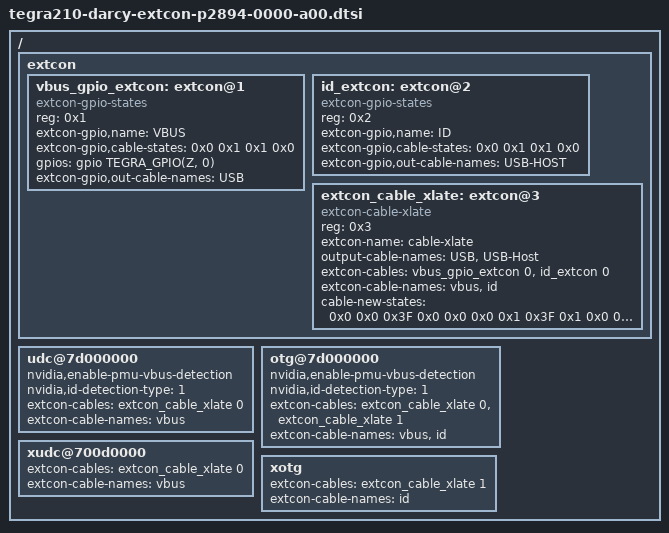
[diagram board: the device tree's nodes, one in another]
/*
 * Copyright (c) 2015-2016, NVIDIA CORPORATION.  All rights reserved.
 *
 * This program is free software; you can redistribute it and/or modify it
 * under the terms and conditions of the GNU General Public License,
 * version 2, as published by the Free Software Foundation.
 *
 * This program is distributed in the hope it will be useful, but WITHOUT
 * ANY WARRANTY; without even the implied warranty of MERCHANTABILITY or
 * FITNESS FOR A PARTICULAR PURPOSE.  See the GNU General Public License for
 * more details.
 */

/ {
	extcon {
		vbus_gpio_extcon: extcon@1 {
			compatible = "extcon-gpio-states";
			reg = <0x1>;
			extcon-gpio,name = "VBUS";
			extcon-gpio,cable-states = <0x0 0x1
						    0x1 0x0>;
			gpios = <&gpio TEGRA_GPIO(Z, 0) 0>;
			extcon-gpio,out-cable-names = "USB";
			#extcon-cells = <1>;
		};

		id_extcon: extcon@2 {
			compatible = "extcon-gpio-states";
			reg = <0x2>;
			extcon-gpio,name = "ID";
			extcon-gpio,cable-states = <0x0 0x1
						0x1 0x0>;
			extcon-gpio,out-cable-names = "USB-HOST";
			#extcon-cells = <1>;
		};

		extcon_cable_xlate: extcon@3 {
			compatible = "extcon-cable-xlate";
			reg = <0x3>;
			extcon-name = "cable-xlate";
			output-cable-names = "USB", "USB-Host";
			extcon-cables = <&vbus_gpio_extcon 0 &id_extcon 0>;
			extcon-cable-names = "vbus", "id";
			cable-new-states = <0x0    0x0    0x3F    0x0    0x0
					0x0     0x1     0x3F    0x1   0x0
					0x0     0x2     0x3F    0x2   0x0
					0x2     0x3     0x3F    0x2   0x0
					0x2     0x1     0x3F    0x2   0x0
					0x1     0x0     0x3F    0x0   0x0
					0x3     0x0     0x3F    0x0   0x0
					0x3     0x1     0x3F    0x0   0x0
					0x2     0x0     0x3F    0x0   0x0>;
			#extcon-cells = <1>;
		};
	};

	udc@7d000000 {
		nvidia,enable-pmu-vbus-detection;
		nvidia,id-detection-type = <1>;
		extcon-cables = <&extcon_cable_xlate 0>;
		extcon-cable-names = "vbus";
	};

	otg@7d000000 {
		nvidia,enable-pmu-vbus-detection;
		nvidia,id-detection-type = <1>;
		extcon-cables = <&extcon_cable_xlate 0 &extcon_cable_xlate 1>;
		extcon-cable-names = "vbus", "id";
	};

	xudc@700d0000 {
		extcon-cables = <&extcon_cable_xlate 0>;
		extcon-cable-names = "vbus";
	};

	xotg {
		extcon-cables = <&extcon_cable_xlate 1>;
		extcon-cable-names = "id";
	};
};
